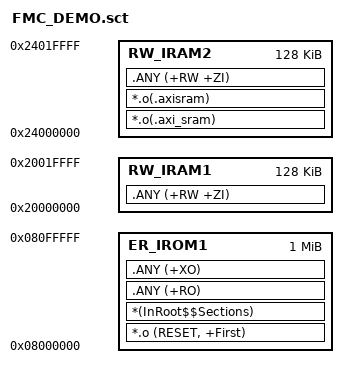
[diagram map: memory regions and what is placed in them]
; *************************************************************
; *** Scatter-Loading Description File generated by uVision ***
; *************************************************************

LR_IROM1 0x08000000 0x00100000  {    ; load region size_region (1 MB Flash)
  ER_IROM1 0x08000000 0x00100000  {  ; load address = execution address
   *.o (RESET, +First)
   *(InRoot$$Sections)
   .ANY (+RO)
   .ANY (+XO)
  }
  RW_IRAM1 0x20000000 0x00020000  {  ; DTCM 128KB — CPU only, DMA1/DMA2 cannot access
   .ANY (+RW +ZI)
  }
  RW_IRAM2 0x24000000 0x00020000  {  ; AXI SRAM 128KB — DMA-accessible, use for DMA buffers
   *.o(.axi_sram)                     ; DMA buffers placed via __attribute__((section(".axi_sram")))
   *.o(.axisram)                      ; ADC capture buffer
   .ANY (+RW +ZI)
  }
}

